# ATSAMV71Q21 register map
Vendor: Microchip Technology; Series: SAMV71; File version: 0
CPU: CM7 r1p1, little endian, MPU, FPU, 3 interrupt priority bits
Registers are 32-bit, access not given, no defined reset value unless marked. A register's access mark holds for its fields unless they carry their own. Offsets are from the block's base; [hi:lo] are bit positions; {n}, {i} and the like mark numbered series.

## ACC — Analog Comparator Controller
Base 0x40044000; register names take the prefix ACC_
0x00 ACC_CR wo — Control Register
  [0] SWRST — Software Reset
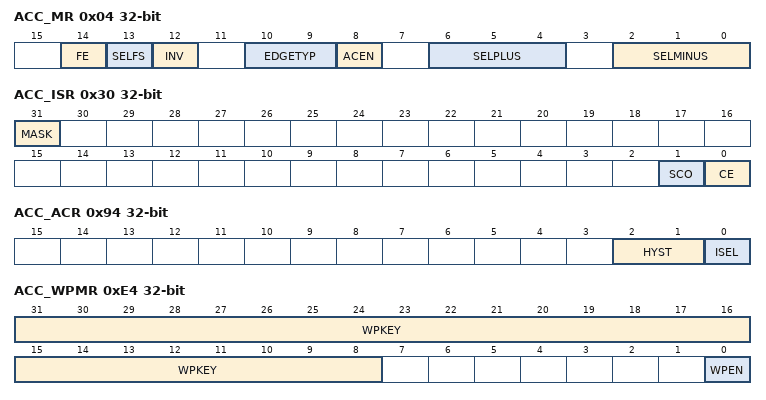
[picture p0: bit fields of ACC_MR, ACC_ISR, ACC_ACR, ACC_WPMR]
0x04 ACC_MR — Mode Register
  [14] FE — Fault Enable
    0=DIS (The FAULT output is tied to 0.); 1=EN (The FAULT output is driven by the signal defined by SELFS.)
  [13] SELFS — Selection Of Fault Source
    0=CE (The CE flag is used to drive the FAULT output.); 1=OUTPUT (The output of the analog comparator flag is used to drive the FAULT output.)
  [12] INV — Invert Comparator Output
    0=DIS (Analog comparator output is directly processed.); 1=EN (Analog comparator output is inverted prior to being processed.)
  [10:9] EDGETYP — Edge Type
    0=RISING (Only rising edge of comparator output); 1=FALLING (Falling edge of comparator output); 2=ANY (Any edge of comparator output)
  [8] ACEN — Analog Comparator Enable
    0=DIS (Analog comparator disabled.); 1=EN (Analog comparator enabled.)
  [6:4] SELPLUS — Selection For Plus Comparator Input
    {v}=AFE0_AD{v} (Select AFE0_AD{v}) (v=0..5); 6=AFE1_AD0 (Select AFE1_AD0); 7=AFE1_AD1 (Select AFE1_AD1)
  [2:0] SELMINUS — Selection for Minus Comparator Input
    0=TS (Select TS); 1=VREFP (Select VREFP); 2=DAC0 (Select DAC0); 3=DAC1 (Select DAC1); {v}=AFE0_AD{v-4} (Select AFE0_AD{v-4}) (v=4..7)
0x24 ACC_IER wo — Interrupt Enable Register
  [0] CE — Comparison Edge
0x28 ACC_IDR wo — Interrupt Disable Register
  [0] CE — Comparison Edge
0x2C ACC_IMR ro — Interrupt Mask Register
  [0] CE — Comparison Edge
0x30 ACC_ISR ro — Interrupt Status Register
  [31] MASK — Flag Mask
  [1] SCO — Synchronized Comparator Output
  [0] CE — Comparison Edge (cleared on read)
0x94 ACC_ACR — Analog Control Register
  [2:1] HYST — Hysteresis Selection
  [0] ISEL — Current Selection
    0=LOPW (Low-power option.); 1=HISP (High-speed option.)
0xE4 ACC_WPMR — Write Protection Mode Register
  [31:8] WPKEY — Write Protection Key
    0x414343=PASSWD (Writing any other value in this field aborts the write operation of the WPEN bit.Always reads as 0.)
  [0] WPEN — Write Protection Enable
0xE8 ACC_WPSR ro — Write Protection Status Register
  [0] WPVS — Write Protection Violation Status
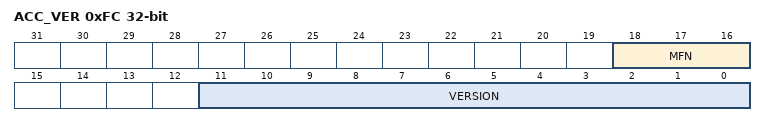
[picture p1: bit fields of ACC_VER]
0xFC ACC_VER ro — Version Register
  [18:16] MFN — Metal Fix Number
  [11:0] VERSION — Version of the Hardware Module

## CHIPID — Chip Identifier
Base 0x400E0940; register names take the prefix CHIPID_
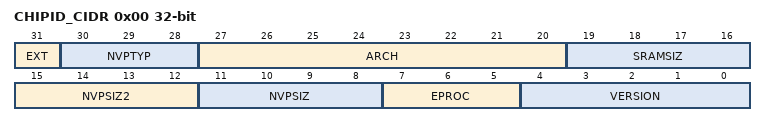
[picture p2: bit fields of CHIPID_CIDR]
0x00 CHIPID_CIDR ro — Chip ID Register
  [31] EXT — Extension Flag
  [30:28] NVPTYP — Nonvolatile Program Memory Type
    0=ROM; 1=ROMLESS (ROMless or on-chip Flash); 2=FLASH (Embedded Flash Memory); 3=ROM_FLASH (ROM and Embedded Flash Memory- NVPSIZ is ROM size- NVPSIZ2 is Flash size); 4=SRAM (SRAM emulating ROM)
  [27:20] ARCH — Architecture Identifier
    18=SAMV71
  [19:16] SRAMSIZ — Internal SRAM Size
    0=_48K (48 Kbytes); 1=_192K (192 Kbytes); 2=_384K (384 Kbytes); 3=_6K (6 Kbytes); 4=_24K (24 Kbytes); 5=_4K (4 Kbytes); 6=_80K (80 Kbytes); 7=_160K (160 Kbytes); 8=_8K (8 Kbytes); 9=_16K (16 Kbytes); 10=_32K (32 Kbytes); 11=_64K (64 Kbytes); 12=_128K (128 Kbytes); 13=_256K (256 Kbytes); 14=_96K (96 Kbytes); 15=_512K (512 Kbytes)
  [15:12] NVPSIZ2 — Second Nonvolatile Program Memory Size
    0=NONE; 1=_8K (8 Kbytes); 2=_16K (16 Kbytes); 3=_32K (32 Kbytes); 5=_64K (64 Kbytes); 7=_128K (128 Kbytes); 9=_256K (256 Kbytes); 10=_512K (512 Kbytes); 12=_1024K (1024 Kbytes); 14=_2048K (2048 Kbytes)
  [11:8] NVPSIZ — Nonvolatile Program Memory Size
    0=NONE; 1=_8K (8 Kbytes); 2=_16K (16 Kbytes); 3=_32K (32 Kbytes); 5=_64K (64 Kbytes); 7=_128K (128 Kbytes); 8=_160K (160 Kbytes); 9=_256K (256 Kbytes); 10=_512K (512 Kbytes); 12=_1024K (1024 Kbytes); 14=_2048K (2048 Kbytes)
  [7:5] EPROC — Embedded Processor
    0=SAMx7 (Cortex-M7); 1=ARM946ES; 2=ARM7TDMI; 3=CM3 (Cortex-M3); 4=ARM920T; 5=ARM926EJS; 6=CA5 (Cortex-A5); 7=CM4 (Cortex-M4)
  [4:0] VERSION — Version of the Device
0x04 CHIPID_EXID ro — Chip ID Extension Register
  [31:0] EXID — Chip ID Extension
